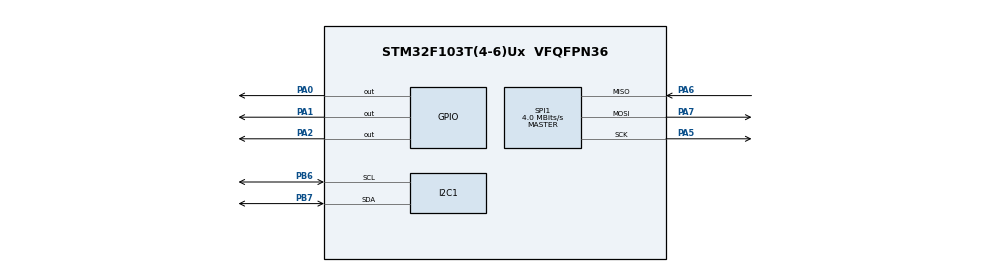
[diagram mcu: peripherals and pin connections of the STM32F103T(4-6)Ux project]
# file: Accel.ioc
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Dma.I2C1_RX.0.Direction=DMA_PERIPH_TO_MEMORY
Dma.I2C1_RX.0.Instance=DMA1_Channel7
Dma.I2C1_RX.0.MemDataAlignment=DMA_MDATAALIGN_BYTE
Dma.I2C1_RX.0.MemInc=DMA_MINC_ENABLE
Dma.I2C1_RX.0.Mode=DMA_NORMAL
Dma.I2C1_RX.0.PeriphDataAlignment=DMA_PDATAALIGN_BYTE
Dma.I2C1_RX.0.PeriphInc=DMA_PINC_DISABLE
Dma.I2C1_RX.0.Priority=DMA_PRIORITY_LOW
Dma.I2C1_TX.1.Direction=DMA_MEMORY_TO_PERIPH
Dma.I2C1_TX.1.Instance=DMA1_Channel6
Dma.I2C1_TX.1.MemDataAlignment=DMA_MDATAALIGN_BYTE
Dma.I2C1_TX.1.MemInc=DMA_MINC_ENABLE
Dma.I2C1_TX.1.Mode=DMA_NORMAL
Dma.I2C1_TX.1.PeriphDataAlignment=DMA_PDATAALIGN_BYTE
Dma.I2C1_TX.1.PeriphInc=DMA_PINC_DISABLE
Dma.I2C1_TX.1.Priority=DMA_PRIORITY_LOW
Dma.Request0=I2C1_RX
Dma.Request1=I2C1_TX
Dma.Request2=SPI1_RX
Dma.Request3=SPI1_TX
Dma.SPI1_RX.2.Direction=DMA_PERIPH_TO_MEMORY
Dma.SPI1_RX.2.Instance=DMA1_Channel2
Dma.SPI1_RX.2.MemDataAlignment=DMA_MDATAALIGN_BYTE
Dma.SPI1_RX.2.MemInc=DMA_MINC_ENABLE
Dma.SPI1_RX.2.Mode=DMA_NORMAL
Dma.SPI1_RX.2.PeriphDataAlignment=DMA_PDATAALIGN_BYTE
Dma.SPI1_RX.2.PeriphInc=DMA_PINC_DISABLE
Dma.SPI1_RX.2.Priority=DMA_PRIORITY_LOW
Dma.SPI1_TX.3.Direction=DMA_MEMORY_TO_PERIPH
Dma.SPI1_TX.3.Instance=DMA1_Channel3
Dma.SPI1_TX.3.MemDataAlignment=DMA_MDATAALIGN_BYTE
Dma.SPI1_TX.3.MemInc=DMA_MINC_ENABLE
Dma.SPI1_TX.3.Mode=DMA_NORMAL
Dma.SPI1_TX.3.PeriphDataAlignment=DMA_PDATAALIGN_BYTE
Dma.SPI1_TX.3.PeriphInc=DMA_PINC_DISABLE
Dma.SPI1_TX.3.Priority=DMA_PRIORITY_LOW
I2C1.NoStretchMode=I2C_NOSTRETCH_ENABLE
I2C1.OwnAddress=10
Mcu.Family=STM32F1
Mcu.Name=STM32F103T(4-6)Ux
Mcu.Package=VFQFPN36
NVIC.DMA1_Channel2_IRQn=true\:0\:0\:false\:false\:true\:false\:true\:true
NVIC.DMA1_Channel3_IRQn=true\:0\:0\:false\:false\:true\:false\:true\:true
NVIC.DMA1_Channel6_IRQn=true\:0\:0\:false\:false\:true\:false\:true\:true
NVIC.DMA1_Channel7_IRQn=true\:0\:0\:false\:false\:true\:false\:true\:true
NVIC.I2C1_ER_IRQn=true\:0\:0\:false\:false\:true\:true\:true\:true
NVIC.I2C1_EV_IRQn=true\:0\:0\:false\:false\:true\:true\:true\:true
NVIC.PriorityGroup=NVIC_PRIORITYGROUP_4
NVIC.SPI1_IRQn=true\:0\:0\:false\:false\:true\:true\:true\:true
PA0-WKUP.Signal=GPIO_Output
PA1.Signal=GPIO_Output
PA2.Signal=GPIO_Output
PA5.Mode=Full_Duplex_Master
PA5.Signal=SPI1_SCK
PA6.Mode=Full_Duplex_Master
PA6.Signal=SPI1_MISO
PA7.Mode=Full_Duplex_Master
PA7.Signal=SPI1_MOSI
PB6.Mode=I2C
PB6.Signal=I2C1_SCL
PB7.Mode=I2C
PB7.Signal=I2C1_SDA
ProjectManager.HeapSize=0x200
ProjectManager.StackSize=0x400
ProjectManager.TargetToolchain=Makefile
RCC.APB1Freq_Value=8000000
RCC.APB2Freq_Value=8000000
SPI1.CalculateBaudRate=4.0 MBits/s
SPI1.Direction=SPI_DIRECTION_2LINES
SPI1.Mode=SPI_MODE_MASTER
SPI1.VirtualType=VM_MASTER
VP_SYS_VS_ND.Mode=No_Debug
board=custom

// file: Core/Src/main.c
/* USER CODE BEGIN Header */
/**
  ******************************************************************************
  * @file           : main.c
  * @brief          : Main program body
  ******************************************************************************
  * @attention
  *
  * Copyright (c) 2025 STMicroelectronics.
  * All rights reserved.
  *
  * This software is licensed under terms that can be found in the LICENSE file
  * in the root directory of this software component.
  * If no LICENSE file comes with this software, it is provided AS-IS.
  *
  ******************************************************************************
  */
/* USER CODE END Header */
#include "main.h"
#include "dma.h"
#include "i2c.h"
#include "spi.h"
#include "gpio.h"

void SystemClock_Config(void);

int main(void)
{

  /* MCU Configuration--------------------------------------------------------*/

  /* Reset of all peripherals, Initializes the Flash interface and the Systick. */
  HAL_Init();

  /* Configure the system clock */
  SystemClock_Config();

  /* Initialize all configured peripherals */
  MX_GPIO_Init();
  MX_DMA_Init();
  MX_I2C1_Init();
  MX_SPI1_Init();
  /* USER CODE BEGIN 2 */
  // HAL_I2C_EnableListen_IT(&hi2c1);
  uint8_t buffer[32] = {1,2};
  // HAL_I2C_EnableListen_IT(&hi2c1);
  while (HAL_I2C_GetState(&hi2c1) != HAL_I2C_STATE_READY);
  HAL_I2C_EnableListen_IT(&hi2c1);

  // Receiving frame 1 data
  if (HAL_I2C_Slave_Seq_Receive_DMA(&hi2c1, buffer, sizeof(buffer), I2C_FIRST_FRAME) != HAL_OK)
    HAL_GPIO_WritePin(GPIOA, GPIO_PIN_0, GPIO_PIN_SET);

  while (HAL_I2C_GetState(&hi2c1) != HAL_I2C_STATE_LISTEN); // Wait for frame 1 finish
  while ((hi2c1.Instance->SR1 & I2C_SR1_ADDR) != I2C_SR1_ADDR); // Wait for address byte of frame 2
  // Sending frame 2 data
  if (HAL_I2C_Slave_Seq_Transmit_DMA(&hi2c1, buffer, 4, I2C_LAST_FRAME) != HAL_OK)
    HAL_GPIO_WritePin(GPIOA, GPIO_PIN_0, GPIO_PIN_SET);

  // QUESTION?

  /* USER CODE END 2 */

  /* Infinite loop */
  while (1)
  {

  }
}

void SystemClock_Config(void)
{
  RCC_OscInitTypeDef RCC_OscInitStruct = {0};
  RCC_ClkInitTypeDef RCC_ClkInitStruct = {0};

  /** Initializes the RCC Oscillators according to the specified parameters
  * in the RCC_OscInitTypeDef structure.
  */
  RCC_OscInitStruct.OscillatorType = RCC_OSCILLATORTYPE_HSI;
  RCC_OscInitStruct.HSIState = RCC_HSI_ON;
  RCC_OscInitStruct.HSICalibrationValue = RCC_HSICALIBRATION_DEFAULT;
  RCC_OscInitStruct.PLL.PLLState = RCC_PLL_NONE;
  if (HAL_RCC_OscConfig(&RCC_OscInitStruct) != HAL_OK)
  {
    Error_Handler();
  }

  /** Initializes the CPU, AHB and APB buses clocks
  */
  RCC_ClkInitStruct.ClockType = RCC_CLOCKTYPE_HCLK|RCC_CLOCKTYPE_SYSCLK
                              |RCC_CLOCKTYPE_PCLK1|RCC_CLOCKTYPE_PCLK2;
  RCC_ClkInitStruct.SYSCLKSource = RCC_SYSCLKSOURCE_HSI;
  RCC_ClkInitStruct.AHBCLKDivider = RCC_SYSCLK_DIV1;
  RCC_ClkInitStruct.APB1CLKDivider = RCC_HCLK_DIV1;
  RCC_ClkInitStruct.APB2CLKDivider = RCC_HCLK_DIV1;

  if (HAL_RCC_ClockConfig(&RCC_ClkInitStruct, FLASH_LATENCY_0) != HAL_OK)
  {
    Error_Handler();
  }
}

/* USER CODE BEGIN 4 */

extern void HAL_I2C_AddrCallback(I2C_HandleTypeDef *hi2c, uint8_t TransferDirection, uint16_t AddrMatchCode)
{
  HAL_GPIO_WritePin(GPIOA, GPIO_PIN_2, GPIO_PIN_SET);
}
/* USER CODE END 4 */

void Error_Handler(void)
{
  __disable_irq();
  while (1)
  {
  }
}
